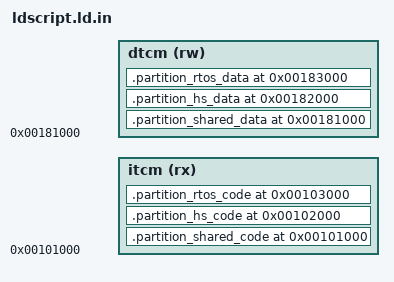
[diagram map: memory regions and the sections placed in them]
#include <liblwriscv/g_lwriscv_config.h>

OUTPUT_ARCH( "riscv" )
ENTRY(startup)
MEMORY {
    dtcm (rw) : ORIGIN = 0x0000000000181000, LENGTH = LWRISCV_APP_DMEM_LIMIT
    itcm (rx) : ORIGIN = 0x0000000000101000, LENGTH = LWRISCV_APP_IMEM_LIMIT
}
SECTIONS
{
  .partition_shared_code 0x101000 :
  {
      *liblwriscv.a:(.text.* .rodata*)
      . = ALIGN(0x1000);
  } > itcm
  ASSERT(SIZEOF(.partition_shared_code) <= 0x1000, ".partition_shared_code size too large")

  .partition_hs_code 0x102000 :
  {
      KEEP(*(.text.partition_1_startup))
      . = ALIGN(4);
      KEEP(*(.text.partition_1_trap_handler))
      *partition_1_main.o(.text.*)
      *partition_1_main.o(.rodata.* .srodata*)
      . = ALIGN(0x1000);
  } > itcm
  ASSERT(SIZEOF(.partition_hs_code) <= 0x1000, ".partition_hs_code size too large")

  .partition_rtos_code 0x103000:
  {
      KEEP(*(.text.partition_0_startup))
      . = ALIGN(4);
      KEEP(*(.text.partition_0_trap_handler))
      *partition_0_main.o(.text.*)
      *partition_0_main.o(.rodata.* .srodata*)
      . = ALIGN(0x1000);
  } > itcm
  ASSERT(SIZEOF(.partition_rtos_code) <= 0x1000, ".partition_rtos_code size too large")
  PROVIDE(__fmc_imem_size = . - ORIGIN(itcm));

  // DATA
  .partition_shared_data 0x181000:
  {
    . = ALIGN(0x1000);
    *liblwriscv.a:(.data* .data.*)
    *liblwriscv.a:(.bss* .sbss*)
    *(.partition_shared_data* .partition_shared_data.*)
    . = ALIGN(0x100);
  } > dtcm
  ASSERT(SIZEOF(.partition_shared_data) < 0x1000, ".partition_shared_data size too large")
  PROVIDE(__partition_shared_data_start = ADDR(.partition_shared_data));

  .partition_hs_data 0x182000:
  {
    . = ALIGN(0x1000);
    *partition_1_main.o(.data .data.*)
    *partition_1_main.o(.bss .bss.* .sbss*)
    . = ALIGN(0x10); // stack alignment
    _partition_1_stack_bottom = . ;
    . += 512 ;
    _partition_1_stack_top = . ;
    . = ALIGN(0x100);
  } > dtcm
  ASSERT(SIZEOF(.partition_hs_data) < 0x1000, ".partition_hs_data size too large")

  .partition_rtos_data 0x183000:
  {
    . = ALIGN(0x1000);
    *partition_0_main.o(.data .data.*)
    *partition_0_main.o(.bss .bss.* .sbss*)
    . = ALIGN(0x10); // stack alignment
    _partition_0_stack_bottom = . ;
    . += 1024 ;
    _partition_0_stack_top = . ;
    . = ALIGN(0x100);
  } > dtcm

  ASSERT(SIZEOF(.partition_hs_data) < 0x1000, ".partition_rtos_data size too large")
  PROVIDE(__fmc_dmem_size = . - ORIGIN(dtcm));
}
